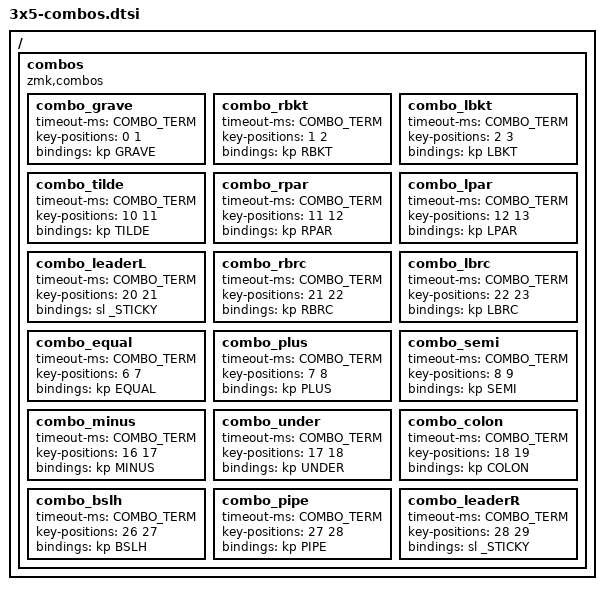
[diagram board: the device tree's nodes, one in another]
// Combos
// note: consider combo declaration as in https://github.com/AlaaSaadAbdo/zmk-config/blob/master/config/combos34.dtsi

#define COMBO_TERM 25

/* Key index
 0  1  2  3  4         5  6  7  8  9
10 11 12 13 14        15 16 17 18 19
20 21 22 23 24        25 26 27 28 29
        30 31 32    33 34 35         */

/ {
    combos {
        compatible = "zmk,combos";
        combo_grave {
            timeout-ms = <COMBO_TERM>;
            key-positions = <0 1>;
            bindings = <&kp GRAVE>;
        };
        combo_rbkt {
            timeout-ms = <COMBO_TERM>;
            key-positions = <1 2>;
            bindings = <&kp RBKT>;
        };
        combo_lbkt {
            timeout-ms = <COMBO_TERM>;
            key-positions = <2 3>;
            bindings = <&kp LBKT>;
        };
        combo_tilde {
            timeout-ms = <COMBO_TERM>;
            key-positions = <10 11>;
            bindings = <&kp TILDE>;
        };
        combo_rpar {
            timeout-ms = <COMBO_TERM>;
            key-positions = <11 12>;
            bindings = <&kp RPAR>;
        };
        combo_lpar {
            timeout-ms = <COMBO_TERM>;
            key-positions = <12 13>;
            bindings = <&kp LPAR>;
        };
        combo_leaderL {
            timeout-ms = <COMBO_TERM>;
            key-positions = <20 21>;
            bindings = <&sl _STICKY>;
        };
        combo_rbrc {
            timeout-ms = <COMBO_TERM>;
            key-positions = <21 22>;
            bindings = <&kp RBRC>;
        };
        combo_lbrc {
            timeout-ms = <COMBO_TERM>;
            key-positions = <22 23>;
            bindings = <&kp LBRC>;
        };

        combo_equal {
            timeout-ms = <COMBO_TERM>;
            key-positions = <6 7>;
            bindings = <&kp EQUAL>;
        };
        combo_plus {
            timeout-ms = <COMBO_TERM>;
            key-positions = <7 8>;
            bindings = <&kp PLUS>;
        };
        combo_semi {
            timeout-ms = <COMBO_TERM>;
            key-positions = <8 9>;
            bindings = <&kp SEMI>;
        };
        combo_minus {
            timeout-ms = <COMBO_TERM>;
            key-positions = <16 17>;
            bindings = <&kp MINUS>;
        };
        combo_under {
            timeout-ms = <COMBO_TERM>;
            key-positions = <17 18>;
            bindings = <&kp UNDER>;
        };
        combo_colon {
            timeout-ms = <COMBO_TERM>;
            key-positions = <18 19>;
            bindings = <&kp COLON>;
        };
        combo_bslh {
            timeout-ms = <COMBO_TERM>;
            key-positions = <26 27>;
            bindings = <&kp BSLH>;
        };
        combo_pipe {
            timeout-ms = <COMBO_TERM>;
            key-positions = <27 28>;
            bindings = <&kp PIPE>;
        };
        combo_leaderR {
            timeout-ms = <COMBO_TERM>;
            key-positions = <28 29>;
            bindings = <&sl _STICKY>;
        };
    };
};

